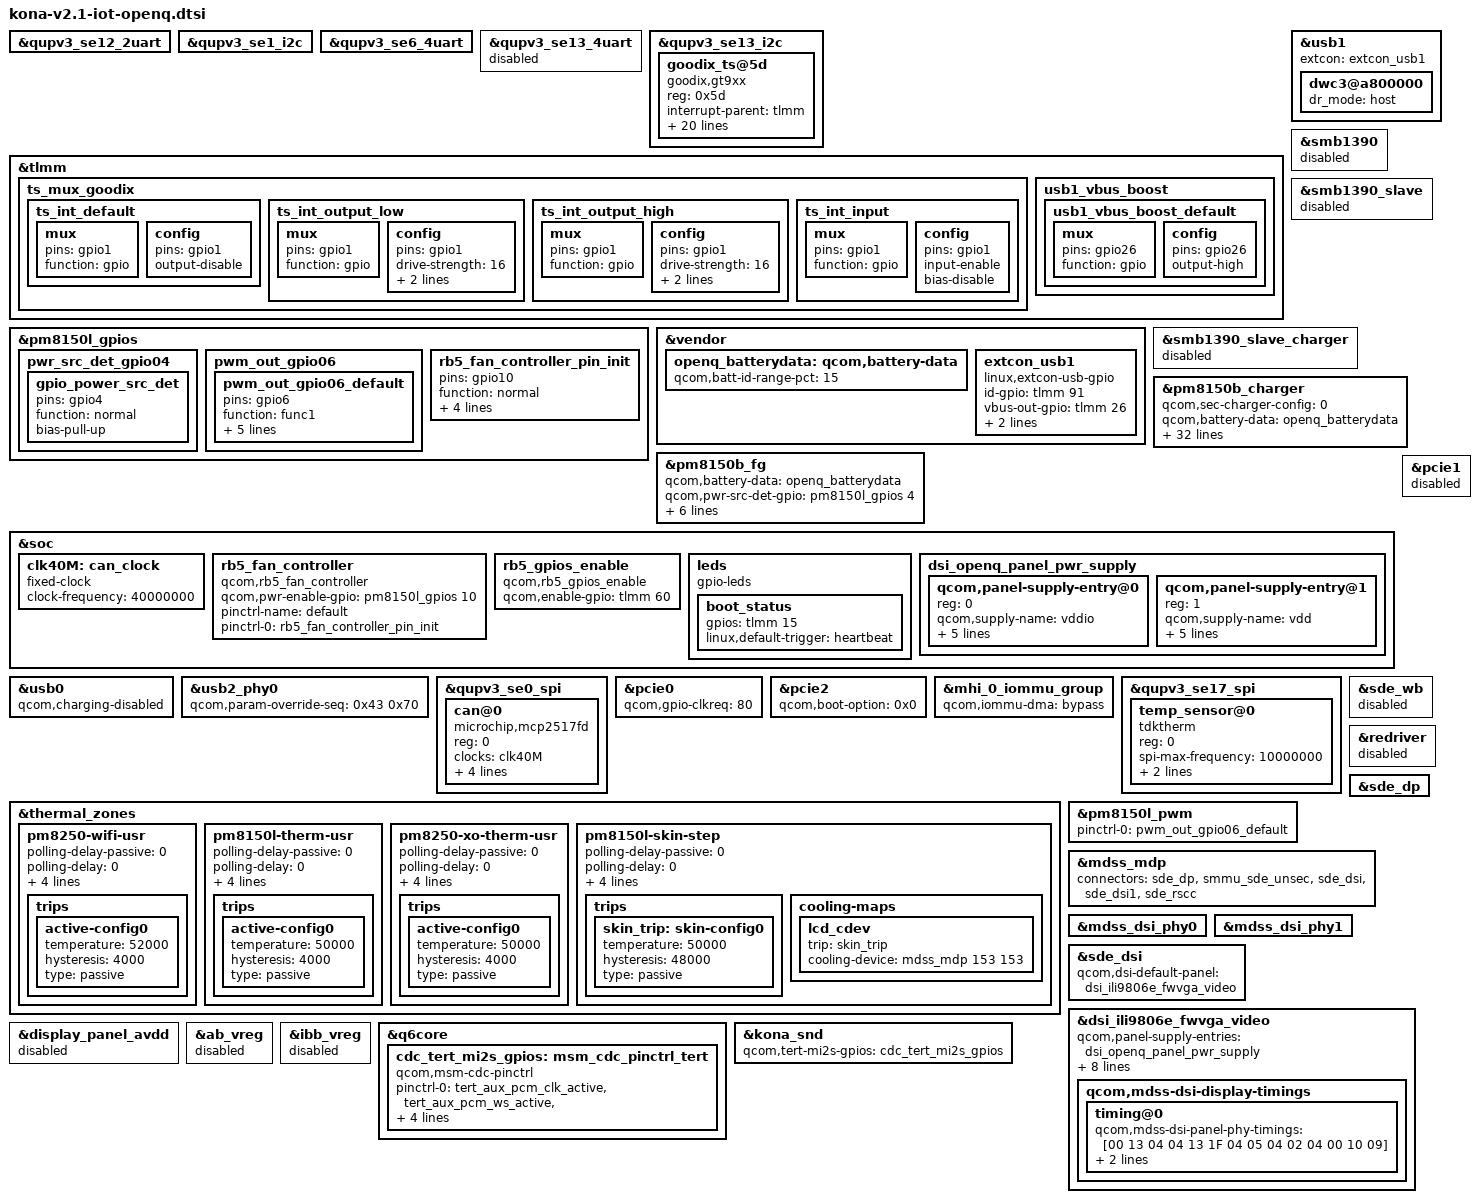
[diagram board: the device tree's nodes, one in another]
#include "kona-qrd.dtsi"
#include "kona-iot-openq-audio.dtsi"
#include "camera/kona-camera-sensor-openq.dtsi"
#include "display/dsi-panel-ili9806e-fwvga-video.dtsi"

&qupv3_se12_2uart {
	status = "okay";
};

&qupv3_se1_i2c {
	status = "okay";
};

&qupv3_se6_4uart {
	status = "ok";
};

&qupv3_se13_4uart {
	status = "disabled";
};

&qupv3_se13_i2c {
	status = "ok";
	goodix_ts@5d {
		compatible = "goodix,gt9xx";
		reg = <0x5d>;
		interrupt-parent = <&tlmm>;
		interrupts = <1 0x2800>;
		pinctrl-names = "default", "int-output-low","int-output-high", "int-input";
		pinctrl-0 = <&ts_int_default>;
		pinctrl-1 = <&ts_int_output_low>;
		pinctrl-2 = <&ts_int_output_high>;
		pinctrl-3 = <&ts_int_input>;
		reset-gpios = <&tlmm 38 0x00>;
		irq-gpios = <&tlmm 1 0x2800>;
		irq-flags = <2>;
		vdd_ana-supply = <&pm8150a_l11>;
		vcc_i2c-supply = <&pm8150_s4>;
		touchscreen-max-id = <5>;
		touchscreen-size-x = <480>;
		touchscreen-size-y = <852>;
		goodix,driver-send-cfg = <1>;
		goodix,int-sync = <1>;
		goodix,power-off-sleep = <1>;
		goodix,cfg-group0 = [
			42 D0 02 00 05 05 75 01 01 0F 24
			0F 64 3C 03 05 00 00 00 02 00 00
			00 16 19 1C 14 8C 0E 0E 24 00 31
			0D 00 00 00 83 33 1D 00 41 00 00
			00 00 00 08 0A 00 2B 1C 3C 94 D5
			03 08 00 00 04 93 1E 00 82 23 00
			74 29 00 69 2F 00 5F 37 00 5F 20
			40 60 00 F0 40 30 55 50 27 00 00
			00 00 00 00 00 00 00 00 00 00 00
			00 00 00 00 00 00 00 14 19 00 00
			50 50 02 04 06 08 0A 0C 0E 10 12
			14 16 18 1A 1C 00 00 00 00 00 00
			00 00 00 00 00 00 00 00 00 00 1D
			1E 1F 20 21 22 24 26 28 29 2A 1C
			18 16 14 13 12 10 0F 0C 0A 08 06
			04 02 00 00 00 00 00 00 00 00 00
			00 00 00 00 00 00 00 00 9C 01];
		goodix,cfg-group2 = [
			5A E0 01 56 03 0A 05 01 01 0F 23
			0F 50 32 03 05 00 00 FF 7F 01 00
			0F 18 1A 1E 14 89 29 0A 59 5B 09
			06 03 0A 00 02 32 11 55 01 00 00
			00 00 00 32 00 00 2B 2D 67 94 C5
			02 07 00 00 04 DD 31 00 C0 39 00
			A3 44 00 8C 50 00 78 5F 00 78 00
			00 00 00 F0 4A 3A FF FF 27 00 1E
			02 32 1E 02 05 2D 1E 19 00 00 01
			0F 0F 03 04 10 42 F8 0F 19 00 00
			46 32 08 0A 0C 0E 10 12 14 16 18
			1A 00 00 00 00 00 00 00 00 00 00
			00 00 00 00 FF FF FF FF 00 00 2A
			29 28 24 22 20 1F 1E 1D 0E 0C 0A
			08 06 05 04 02 00 00 00 00 00 00
			00 00 00 00 FF FF FF FF FF FF FF
			FF FF FF FF FF FF FF FF 74 01];
	};
};

&tlmm {
	ts_mux_goodix {
		ts_int_default: ts_int_default {
			mux {
				pins = "gpio1";
				function = "gpio";
			};
			config {
				pins = "gpio1";
				output-disable;
			};
		};
		ts_int_output_low: ts_int_output_low {
			mux {
				pins = "gpio1";
				function = "gpio";
			};
			config {
				pins = "gpio1";
				drive-strength = <16>;
				output-enable;
				output-low;
			};
		};
		ts_int_output_high: ts_int_output_high {
			mux {
				pins = "gpio1";
				function = "gpio";
			};
			config {
				pins = "gpio1";
				drive-strength = <16>;
				output-enable;
				output-high;
			};
		};
		ts_int_input: ts_int_input {
			mux {
				pins = "gpio1";
				function = "gpio";
			};
			config {
				pins = "gpio1";
				input-enable;
				bias-disable;
			};
		};
	};
};

&pm8150l_gpios {
	pwr_src_det_gpio04 {
		gpio_power_src_det: gpio_power_src_det {
			pins = "gpio4";
			function = "normal";
			bias-pull-up;
		};
	};

	pwm_out_gpio06 {
		pwm_out_gpio06_default: pwm_out_gpio06_default {
			pins = "gpio6";
			function = "func1";
			bias-disable;
			power-source = <0>;
			output-low;
			qcom,drive-strength = <3>;
			drive-push-pull;
		};
	};

	rb5_fan_controller_pin_init: rb5_fan_controller_pin_init {
		pins = "gpio10";
		function = "normal";
		output-enable;
		input-disable;
		bias-pull-down;
		power-source = <0>;
	};
};

&tlmm {
        usb1_vbus_boost {
                usb1_vbus_boost_default: usb1_vbus_boost_default {
                        mux {
                                pins = "gpio26";
                                function = "gpio";
                        };

                        config {
                                pins = "gpio26";
                                output-high;
                        };
                };
        };
};

&vendor {
        openq_batterydata: qcom,battery-data {
                qcom,batt-id-range-pct = <15>;
                #include "fg-gen4-batterydata-powerizer-3350mah.dtsi"
        };

        extcon_usb1: extcon_usb1 {
                compatible = "linux,extcon-usb-gpio";
                id-gpio = <&tlmm 91 GPIO_ACTIVE_HIGH>;
                vbus-out-gpio = <&tlmm 26 GPIO_ACTIVE_HIGH>;

                pinctrl-names = "default";
                pinctrl-0 = <&usb2_id_det_default
                                &usb1_vbus_boost_default>;
        };
};

&usb1 {
        extcon = <&extcon_usb1>;
	/delete-property/ qcom,default-mode-none;
	dwc3@a800000 {
		dr_mode = "host";
	};
};

&smb1390 {
	status = "disabled";
};

&smb1390_slave {
	status = "disabled";
};

&smb1390_slave_charger {
	status = "disabled";
};

&pm8150b_charger {
	qcom,sec-charger-config = <0>; /* no secondary charger */
	qcom,battery-data = <&openq_batterydata>;
	/delete-property/ qcom,fcc-stepping-enable;
	/delete-property/ qcom,batteryless-platform;
	qcom,usb-icl-ua = <1500000>;
	qcom,hvdcp3-max-icl-ua = <1500000>;
	qcom,hvdcp2-max-icl-ua = <1500000>;
	qcom,fcc-max-ua = <1500000>;
	qcom,fv-max-uv = <4330000>;
	qcom,chg-term-src = <1>; // ADC comparator
	qcom,chg-term-current-ma = <200>; // upper threshold
	qcom,chg-term-base-current-ma = <100>; // lower threshold
	qcom,hold-soc-while-full;
	qcom,soc-scale-mode-en;
	qcom,lpd-disable;
	#io-channel-cells = <1>;
	io-channels = <&pm8150b_fg PSY_IIO_DEBUG_BATTERY>,
		      <&pm8150b_fg PSY_IIO_CAPACITY>,
		      <&pm8150b_fg PSY_IIO_REAL_CAPACITY>,
		      <&pm8150b_fg PSY_IIO_CC_SOC>,
		      <&pm8150b_fg PSY_IIO_CURRENT_NOW>,
		      <&pm8150b_fg PSY_IIO_VOLTAGE_NOW>,
		      <&pm8150b_fg PSY_IIO_VOLTAGE_MAX>,
		      <&pm8150b_fg PSY_IIO_CHARGE_FULL>,
		      <&pm8150b_fg PSY_IIO_RESISTANCE_ID>,
		      <&pm8150b_fg PSY_IIO_TEMP>,
		      <&pm8150b_fg PSY_IIO_CHARGE_COUNTER>,
		      <&pm8150b_fg PSY_IIO_CYCLE_COUNT>,
		      <&pm8150b_fg PSY_IIO_CHARGE_FULL_DESIGN>,
		      <&pm8150b_fg PSY_IIO_TIME_TO_FULL_NOW>,
		      <&pm8150b_vadc ADC5_USB_IN_V_16>,
		      <&pm8150b_vadc ADC5_USB_IN_I>,
		      <&pm8150b_vadc ADC5_SBUx>,
		      <&pm8150b_vadc ADC5_VPH_PWR>,
		      <&pm8150b_vadc ADC5_DIE_TEMP>,
		      <&pm8150b_vadc ADC5_MID_CHG_DIV6>,
		      <&pm8150b_vadc ADC5_CHG_TEMP>;
	io-channel-names ="debug_battery",
			   "capacity",
			   "real_capacity",
			   "cc_soc",
			   "current_now",
			   "voltage_now",
			   "voltage_max",
			   "charge_full",
			   "resistance_id",
			   "temp",
			   "charge_counter",
			   "cycle_count",
			   "charge_full_design",
			   "time_to_full_now",
			   "usb_in_voltage",
			   "usb_in_current",
			   "sbux_res",
			   "vph_voltage",
			   "die_temp",
			   "mid_voltage",
			   "chg_temp";
};

&pm8150b_fg {
	qcom,battery-data = <&openq_batterydata>;
	/delete-property/ qcom,five-pin-battery;
	qcom,pwr-src-det-gpio = <&pm8150l_gpios 4 0>;
	pinctrl-names = "default";
	pinctrl-0 = <&gpio_power_src_det>;
	#io-channel-cells = <1>;
	io-channels = <&pm8150b_charger PSY_IIO_RECHARGE_SOC>,
		<&pm8150b_charger PSY_IIO_CHARGE_DONE>,
		<&pm8150b_charger PSY_IIO_CHARGE_QNOVO_ENABLE>,
		<&pm8150b_charger PSY_IIO_PARALLEL_DISABLE>;
	io-channel-names = "recharge_soc",
			"charge_done",
			"charge_qnovo_enable",
			"parallel_charging_enabled";
};

&soc {
	clk40M: can_clock {
		compatible = "fixed-clock";
		#clock-cells = <0>;
		clock-frequency = <40000000>;
	};

	rb5_fan_controller {
		compatible = "qcom,rb5_fan_controller";
		qcom,pwr-enable-gpio = <&pm8150l_gpios 10 0x0>;
		pinctrl-name = "default";
		pinctrl-0 = <&rb5_fan_controller_pin_init>;
		status = "ok";
	};

	rb5_gpios_enable {
		compatible = "qcom,rb5_gpios_enable";
		qcom,enable-gpio = <&tlmm 60 0x0>;
		status = "ok";
	};

	leds {
		compatible = "gpio-leds";
		boot_status {
			gpios = <&tlmm 15 0>;
			linux,default-trigger = "heartbeat";
		};
	};
};

&usb0 {
	qcom,charging-disabled;
};

&usb2_phy0 {
	qcom,param-override-seq = <0x43 0x70>;
};

&qupv3_se0_spi {
	status = "okay";
	can@0 {
		compatible = "microchip,mcp2517fd";
		reg = <0>;
		clocks = <&clk40M>;
		interrupt-parent = <&tlmm>;
		interrupts = <15 0>;
		interrupt-names = "can_irq";
		spi-max-frequency = <10000000>;
		gpio-controller;
		status = "okay";
	};
};

&pcie0 {
	/delete-property/ qcom,clkreq-gpio;
	qcom,gpio-clkreq = <80>;
};

&pcie1 {
	status = "disabled";
};

&pcie2 {
	qcom,boot-option = <0x0>;
};

&mhi_0_iommu_group {
	qcom,iommu-dma = "bypass";
};

&thermal_zones {
	/delete-node/ modem-lte-sub6-pa1;
	/delete-node/ modem-lte-sub6-pa2;
	/delete-node/ modem-mmw0-usr;
	/delete-node/ modem-mmw1-usr;
	/delete-node/ modem-mmw2-usr;
	/delete-node/ modem-mmw3-usr;
	/delete-node/ modem-skin-usr;
	/delete-node/ modem-wifi-usr;
	/delete-node/ modem-ambient-usr;
	/delete-node/ modem-0-usr;
	/delete-node/ modem-1-usr;
	/delete-node/ modem-streamer-usr;
	/delete-node/ modem-mmw0-mod-usr;
	/delete-node/ modem-mmw1-mod-usr;
	/delete-node/ modem-mmw2-mod-usr;
	/delete-node/ modem-mmw3-mod-usr;

	/delete-node/ skin-therm-usr;
	/delete-node/ skin-therm-step;
	/delete-node/ camera-therm-usr;

	/delete-node/ mmw-pa1-usr;
	/delete-node/ mmw-pa1-step;
	/delete-node/ mmw-pa2-usr;
	/delete-node/ mmw-pa2-step;
	/delete-node/ xo-therm-step;
	/delete-node/ xo-therm-usr;
	/delete-node/ skin-msm-therm-step;

	pm8250-wifi-usr {
		polling-delay-passive = <0>;
		polling-delay = <0>;
		thermal-governor = "user_space";
		thermal-sensors = <&pm8150_adc_tm ADC5_AMUX_THM2_100K_PU>;
		wake-capable-sensor;
		trips {
			active-config0 {
				temperature = <52000>;
				hysteresis = <4000>;
				type = "passive";
			};
		};
	};

	pm8150l-therm-usr {
		polling-delay-passive = <0>;
		polling-delay = <0>;
		thermal-governor = "user_space";
		thermal-sensors = <&pm8150l_adc_tm ADC5_AMUX_THM3_100K_PU>;
		wake-capable-sensor;
		trips {
			active-config0 {
				temperature = <50000>;
				hysteresis = <4000>;
				type = "passive";
			};
		};
	};

	pm8250-xo-therm-usr {
		polling-delay-passive = <0>;
		polling-delay = <0>;
		thermal-governor = "user_space";
		thermal-sensors = <&pm8150_adc_tm ADC5_XO_THERM_100K_PU>;
		wake-capable-sensor;
		trips {
			active-config0 {
				temperature = <50000>;
				hysteresis = <4000>;
				type = "passive";
			};

		};
	};

	pm8150l-skin-step {
		polling-delay-passive = <0>;
		polling-delay = <0>;
		thermal-governor = "step_wise";
		thermal-sensors = <&pm8150l_adc_tm ADC5_AMUX_THM2_100K_PU>;
		wake-capable-sensor;
		trips {
			skin_trip: skin-config0 {
				temperature = <50000>;
				hysteresis = <48000>;
				type = "passive";
			};
		};

		cooling-maps {
			lcd_cdev {
				trip = <&skin_trip>;
				cooling-device = <&mdss_mdp 153 153>;
			};
		};
	};
};

&qupv3_se17_spi {
	status = "okay";
	temp_sensor@0 {
		compatible = "tdktherm";
		reg = <0>; // Chip select ID
		spi-max-frequency = <10000000>; // Can support up to 24 MHz
		spi-cpol;
		spi-cpha;
		status = "okay";
	};
};

&soc {
	dsi_openq_panel_pwr_supply: dsi_openq_panel_pwr_supply {
		#address-cells = <1>;
		#size-cells = <0>;

		qcom,panel-supply-entry@0 {
			reg = <0>;
			qcom,supply-name = "vddio";
			qcom,supply-min-voltage = <1800000>;
			qcom,supply-max-voltage = <1800000>;
			qcom,supply-enable-load = <62000>;
			qcom,supply-disable-load = <80>;
			qcom,supply-post-on-sleep = <20>;
		};

		qcom,panel-supply-entry@1 {
			reg = <1>;
			qcom,supply-name = "vdd";
			qcom,supply-min-voltage = <3300000>;
			qcom,supply-max-voltage = <3300000>;
			qcom,supply-enable-load = <857000>;
			qcom,supply-disable-load = <0>;
			qcom,supply-post-on-sleep = <0>;
		};
	};
};

&pm8150l_pwm {
	status = "ok";
	pinctrl-names = "default";
	pinctrl-0 = <&pwm_out_gpio06_default>;
};

&sde_wb {
	status = "disabled";
};

&redriver {
        status = "disabled";
};

&sde_dp {
	status = "ok";
};

&mdss_mdp {
	connectors = <&sde_dp &smmu_sde_unsec &sde_dsi &sde_dsi1 &sde_rscc>;
};

&mdss_dsi_phy0 {
	/delete-property/ qcom,dsi-pll-ssc-en;
};

&mdss_dsi_phy1 {
	/delete-property/ qcom,dsi-pll-ssc-en;
};

&sde_dsi {
	qcom,dsi-default-panel = <&dsi_ili9806e_fwvga_video>;
};

&dsi_ili9806e_fwvga_video {
	qcom,panel-supply-entries = <&dsi_openq_panel_pwr_supply>;
	qcom,mdss-dsi-bl-pmic-control-type = "bl_ctrl_pwm";
	pwms = <&pm8150l_pwm 0 0>;
	qcom,bl-pmic-pwm-period-usecs = <100>;
	qcom,platform-te-gpio = <&tlmm 66 0>;
	qcom,platform-reset-gpio = <&tlmm 75 0>;
	qcom,dsi-select-clocks = "mux_byte_clk0", "mux_pixel_clk0";
	qcom,mdss-dsi-display-timings {
		timing@0 {
			qcom,mdss-dsi-panel-phy-timings =  [00 13 04 04 13 1F
				04 05 04 02 04 00 10 09];
			qcom,display-topology = <1 0 1>;
			qcom,default-topology-index = <0>;
		};
	};
};

&display_panel_avdd{
	status = "disabled";
};

&ab_vreg{
	status = "disabled";
};

&ibb_vreg{
	status = "disabled";
};

&q6core {
	cdc_tert_mi2s_gpios: msm_cdc_pinctrl_tert {
		compatible = "qcom,msm-cdc-pinctrl";
		pinctrl-names = "aud_active", "aud_sleep";
		pinctrl-0 = <&tert_aux_pcm_clk_active &tert_aux_pcm_ws_active
			&tert_aux_pcm_din_active>;
		pinctrl-1 = <&tert_aux_pcm_clk_sleep &tert_aux_pcm_ws_sleep
			&tert_aux_pcm_din_sleep>;
		#gpio-cells = <0>;
	};
};

&kona_snd {
	/delete-property/ qcom,quat-mi2s-gpios;
	qcom,tert-mi2s-gpios = <&cdc_tert_mi2s_gpios>;
};
